# LM3S6965 register map
Vendor: Texas Instruments; File version: 1.0
Stellaris LM3S6965, подмножество: UART0 и UART1
CPU: CM3 r2p0, little endian, MPU, no FPU, 3 interrupt priority bits
Registers are 32-bit, read-write, reset 0x0 unless marked. A register's access mark holds for its fields unless they carry their own. Offsets are from the block's base; lines under a group give offsets from that group; [hi:lo] are bit positions; {n}, {i} and the like mark numbered series; 'fields as' and 'values as' point back to an identical list; <NAME> marks a mode.

## Memory map
0x4000C000 UART0 size 0x1000 — Универсальный асинхронный приёмопередатчик (PL011)
0x4000D000 UART1 size 0x1000

## Interrupts
5 UART0
6 UART1

## UART0 — Универсальный асинхронный приёмопередатчик (PL011)
Base 0x4000C000
Same registers: UART1 0x4000D000
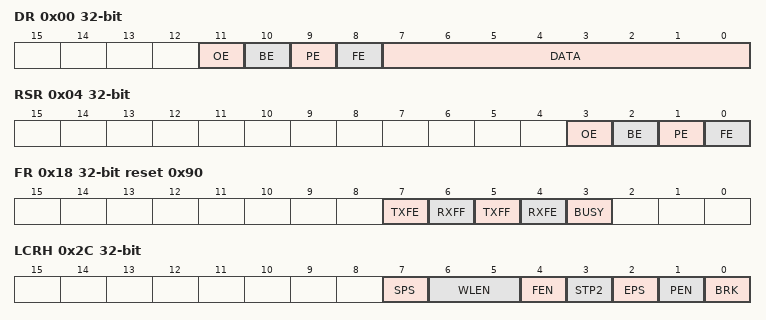
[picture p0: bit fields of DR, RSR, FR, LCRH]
0x00 DR — Данные: запись — в FIFO передатчика, чтение — из FIFO приёмника с флагами ошибок
  [11] OE ro — Переполнение приёмника
  [10] BE ro — Разрыв линии
  [9] PE ro — Ошибка чётности
  [8] FE ro — Ошибка кадра
  [7:0] DATA — Байт данных
0x04 RSR — Состояние приёма; запись сбрасывает ошибки (UARTECR)
  [3] OE — Переполнение приёмника
  [2] BE — Разрыв линии
  [1] PE — Ошибка чётности
  [0] FE — Ошибка кадра
0x18 FR ro reset 0x90 — Флаги
  [7] TXFE — FIFO передатчика пуст
  [6] RXFF — FIFO приёмника полон
  [5] TXFF — FIFO передатчика полон
  [4] RXFE — FIFO приёмника пуст
  [3] BUSY — Передатчик занят
0x20 ILPR — Делитель IrDA для режима низкого потребления
  [7:0] ILPDVSR — Делитель
0x24 IBRD — Целая часть делителя скорости
  [15:0] DIVINT — Целая часть
0x28 FBRD — Дробная часть делителя скорости
  [5:0] DIVFRAC — Дробная часть, 1/64
0x2C LCRH — Формат кадра
  [7] SPS — Фиксированная чётность
  [6:5] WLEN — Длина слова: 0 — 5 бит … 3 — 8 бит
  [4] FEN — FIFO включены
  [3] STP2 — Два стоповых бита
  [2] EPS — Чётность — чётная
  [1] PEN — Чётность включена
  [0] BRK — Послать разрыв
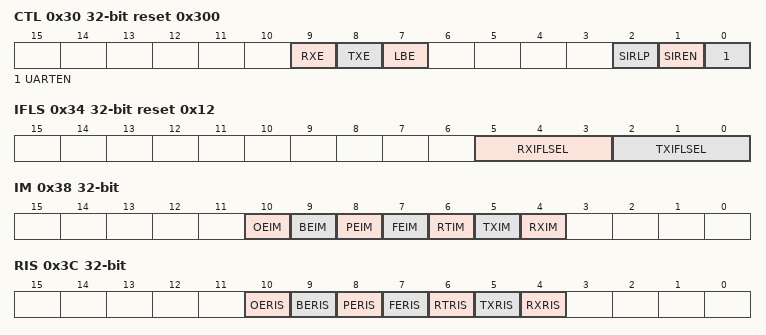
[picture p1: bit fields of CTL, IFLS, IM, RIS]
0x30 CTL reset 0x300 — Управление
  [9] RXE — Приёмник включён
  [8] TXE — Передатчик включён
  [7] LBE — Петля
  [2] SIRLP — IrDA низкого потребления
  [1] SIREN — IrDA включён
  [0] UARTEN — UART включён
0x34 IFLS reset 0x12 — Пороги прерываний FIFO
  [5:3] RXIFLSEL — Порог приёмника
  [2:0] TXIFLSEL — Порог передатчика
0x38 IM — Маска прерываний
  [10] OEIM, [9] BEIM, [8] PEIM, [7] FEIM, [6] RTIM, [5] TXIM, [4] RXIM
0x3C RIS ro — Сырые запросы прерываний
  [10] OERIS, [9] BERIS, [8] PERIS, [7] FERIS, [6] RTRIS, [5] TXRIS, [4] RXRIS
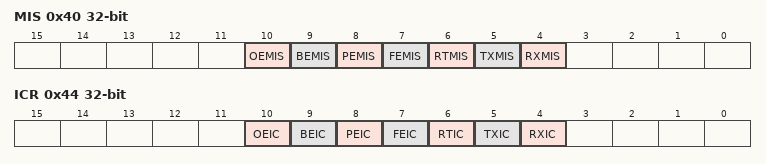
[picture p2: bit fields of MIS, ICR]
0x40 MIS ro — Запросы прерываний после маски
  [10] OEMIS, [9] BEMIS, [8] PEMIS, [7] FEMIS, [6] RTMIS, [5] TXMIS, [4] RXMIS
0x44 ICR wo — Сброс запросов прерываний: 1 сбрасывает бит
  [10] OEIC, [9] BEIC, [8] PEIC, [7] FEIC, [6] RTIC, [5] TXIC, [4] RXIC
